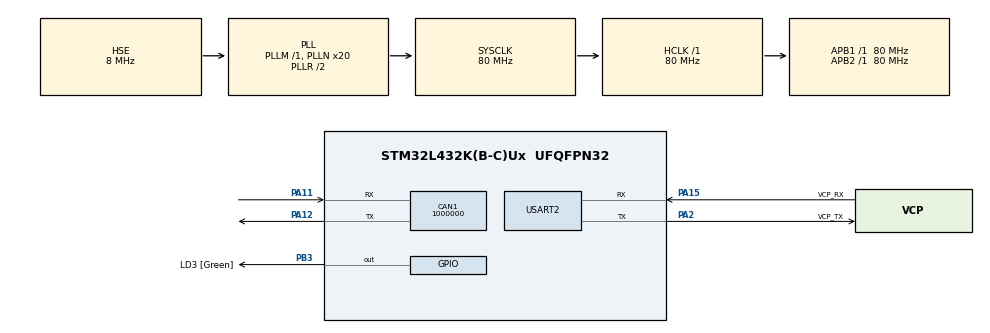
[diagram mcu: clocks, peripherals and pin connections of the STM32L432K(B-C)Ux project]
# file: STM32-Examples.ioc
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CAN1.BS1=CAN_BS1_3TQ
CAN1.CalculateBaudRate=1000000
CAN1.CalculateTimeBit=1000
CAN1.CalculateTimeQuantum=200.0
FREERTOS.INCLUDE_uxTaskGetStackHighWaterMark2=1
FREERTOS.Tasks01=defaultTask,24,128,StartDefaultTask,Default,NULL,Dynamic,NULL,NULL;carReceiveTask,24,400,StartCanReceiveTask,Default,NULL,Static,carReceiveBuffer,carReceiveControlBlock;canTransmitTask,8,400,StartCanTransmitTask,Default,NULL,Static,canTransmitTaskBuffer,canTransmitTaskControlBlock
FREERTOS.configCHECK_FOR_STACK_OVERFLOW=2
FREERTOS.configUSE_NEWLIB_REENTRANT=1
Mcu.Family=STM32L4
Mcu.Name=STM32L432K(B-C)Ux
Mcu.Package=UFQFPN32
NVIC.CAN1_RX0_IRQn=true\:5\:0\:false\:false\:true\:true\:true\:true\:true
NVIC.CAN1_RX1_IRQn=true\:5\:0\:false\:false\:true\:true\:true\:true\:true
NVIC.CAN1_SCE_IRQn=true\:5\:0\:false\:false\:true\:true\:true\:true\:true
NVIC.CAN1_TX_IRQn=true\:5\:0\:false\:false\:true\:true\:true\:true\:true
NVIC.PriorityGroup=NVIC_PRIORITYGROUP_4
NVIC.TIM1_UP_TIM16_IRQn=true\:15\:0\:false\:false\:true\:false\:false\:true\:true
NVIC.TimeBase=TIM1_UP_TIM16_IRQn
NVIC.TimeBaseIP=TIM16
PA0.GPIO_Label=MCO [High speed clock in]
PA0.Mode=HSE-External-Clock-Source-for-LittleOrca
PA0.Signal=RCC_CK_IN
PA11.Mode=CAN_Activate
PA11.Signal=CAN1_RX
PA12.Mode=CAN_Activate
PA12.Signal=CAN1_TX
PA13\ (JTMS-SWDIO).GPIO_Label=SWDIO
PA13\ (JTMS-SWDIO).Mode=Serial_Wire
PA13\ (JTMS-SWDIO).Signal=SYS_JTMS-SWDIO
PA14\ (JTCK-SWCLK).GPIO_Label=SWCLK
PA14\ (JTCK-SWCLK).Mode=Serial_Wire
PA14\ (JTCK-SWCLK).Signal=SYS_JTCK-SWCLK
PA15\ (JTDI).GPIO_Label=VCP_RX
PA15\ (JTDI).Mode=Asynchronous
PA15\ (JTDI).Signal=USART2_RX
PA2.GPIO_Label=VCP_TX
PA2.Mode=Asynchronous
PA2.Signal=USART2_TX
PB3\ (JTDO-TRACESWO).GPIO_Label=LD3 [Green]
PB3\ (JTDO-TRACESWO).Signal=GPIO_Output
PC14-OSC32_IN\ (PC14).Mode=LSE-External-Oscillator
PC14-OSC32_IN\ (PC14).Signal=RCC_OSC32_IN
PC15-OSC32_OUT\ (PC15).Mode=LSE-External-Oscillator
PC15-OSC32_OUT\ (PC15).Signal=RCC_OSC32_OUT
ProjectManager.HeapSize=0x200
ProjectManager.StackSize=0x400
ProjectManager.TargetToolchain=CMake
RCC.ADCFreq_Value=32000000
RCC.AHBFreq_Value=80000000
RCC.APB1Freq_Value=80000000
RCC.APB1TimFreq_Value=80000000
RCC.APB2Freq_Value=80000000
RCC.APB2TimFreq_Value=80000000
RCC.CortexFreq_Value=80000000
RCC.HCLKFreq_Value=80000000
RCC.HSE_VALUE=8000000
RCC.HSI16_VALUE=16000000
RCC.HSI48_VALUE=48000000
RCC.HSI_VALUE=16000000
RCC.MSI_VALUE=4000000
RCC.PLLMUL=RCC_PLLMUL_4
RCC.PLLN=20
RCC.PLLSourceVirtual=RCC_PLLSOURCE_HSE
RCC.SYSCLKFreq_VALUE=80000000
RCC.SYSCLKSource=RCC_SYSCLKSOURCE_PLLCLK
RCC.USBFreq_Value=32000000
RCC.VCOOutputFreq_Value=160000000
USART2.VirtualMode-Asynchronous=VM_ASYNC
VP_FREERTOS_VS_CMSIS_V2.Mode=CMSIS_V2
VP_SYS_VS_tim16.Mode=TIM16
board=NUCLEO-L432KC

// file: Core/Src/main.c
/* USER CODE BEGIN Header */
/**
  ******************************************************************************
  * @file           : main.c
  * @brief          : Main program body
  ******************************************************************************
  * @attention
  *
  * Copyright (c) 2026 STMicroelectronics.
  * All rights reserved.
  *
  * This software is licensed under terms that can be found in the LICENSE file
  * in the root directory of this software component.
  * If no LICENSE file comes with this software, it is provided AS-IS.
  *
  ******************************************************************************
  */
/* USER CODE END Header */
#include "main.h"
#include "cmsis_os.h"

/* USER CODE BEGIN Includes */
#include "ecocar_can.h"
/* USER CODE END Includes */

typedef StaticTask_t osStaticThreadDef_t;

/* USER CODE BEGIN PM */
fdcanBytes_t test_b;
fdcanBytes_t test_b2;
/* USER CODE END PM */

CAN_HandleTypeDef hcan1;

UART_HandleTypeDef huart2;

/* Definitions for defaultTask */
osThreadId_t defaultTaskHandle;
const osThreadAttr_t defaultTask_attributes = {
  .name = "defaultTask",
  .stack_size = 128 * 4,
  .priority = (osPriority_t) osPriorityNormal,
};
/* Definitions for carReceiveTask */
osThreadId_t carReceiveTaskHandle;
uint32_t carReceiveBuffer[ 400 ];
osStaticThreadDef_t carReceiveControlBlock;
const osThreadAttr_t carReceiveTask_attributes = {
  .name = "carReceiveTask",
  .cb_mem = &carReceiveControlBlock,
  .cb_size = sizeof(carReceiveControlBlock),
  .stack_mem = &carReceiveBuffer[0],
  .stack_size = sizeof(carReceiveBuffer),
  .priority = (osPriority_t) osPriorityNormal,
};
/* Definitions for canTransmitTask */
osThreadId_t canTransmitTaskHandle;
uint32_t canTransmitTaskBuffer[ 400 ];
osStaticThreadDef_t canTransmitTaskControlBlock;
const osThreadAttr_t canTransmitTask_attributes = {
  .name = "canTransmitTask",
  .cb_mem = &canTransmitTaskControlBlock,
  .cb_size = sizeof(canTransmitTaskControlBlock),
  .stack_mem = &canTransmitTaskBuffer[0],
  .stack_size = sizeof(canTransmitTaskBuffer),
  .priority = (osPriority_t) osPriorityLow,
};

void SystemClock_Config(void);
static void MX_GPIO_Init(void);
static void MX_CAN1_Init(void);
static void MX_USART2_UART_Init(void);
void StartDefaultTask(void *argument);
void StartCanReceiveTask(void *argument);
void StartCanTransmitTask(void *argument);

int main(void)
{

  /* MCU Configuration--------------------------------------------------------*/

  /* Reset of all peripherals, Initializes the Flash interface and the Systick. */
  HAL_Init();

  /* Configure the system clock */
  SystemClock_Config();

  /* Initialize all configured peripherals */
  MX_GPIO_Init();
  MX_CAN1_Init();
  MX_USART2_UART_Init();

  /* Init scheduler */
  osKernelInitialize();

  /* Create the thread(s) */
  /* creation of defaultTask */
  defaultTaskHandle = osThreadNew(StartDefaultTask, NULL, &defaultTask_attributes);

  /* creation of carReceiveTask */
  carReceiveTaskHandle = osThreadNew(StartCanReceiveTask, NULL, &carReceiveTask_attributes);

  /* creation of canTransmitTask */
  canTransmitTaskHandle = osThreadNew(StartCanTransmitTask, NULL, &canTransmitTask_attributes);

  /* Start scheduler */
  osKernelStart();

  /* We should never get here as control is now taken by the scheduler */

  /* Infinite loop */
  while (1)
  {

  }
}

void SystemClock_Config(void)
{
  RCC_OscInitTypeDef RCC_OscInitStruct = {0};
  RCC_ClkInitTypeDef RCC_ClkInitStruct = {0};

  /** Configure the main internal regulator output voltage
  */
  if (HAL_PWREx_ControlVoltageScaling(PWR_REGULATOR_VOLTAGE_SCALE1) != HAL_OK)
  {
    Error_Handler();
  }

  /** Initializes the RCC Oscillators according to the specified parameters
  * in the RCC_OscInitTypeDef structure.
  */
  RCC_OscInitStruct.OscillatorType = RCC_OSCILLATORTYPE_HSE;
  RCC_OscInitStruct.HSEState = RCC_HSE_BYPASS;
  RCC_OscInitStruct.PLL.PLLState = RCC_PLL_ON;
  RCC_OscInitStruct.PLL.PLLSource = RCC_PLLSOURCE_HSE;
  RCC_OscInitStruct.PLL.PLLM = 1;
  RCC_OscInitStruct.PLL.PLLN = 20;
  RCC_OscInitStruct.PLL.PLLP = RCC_PLLP_DIV7;
  RCC_OscInitStruct.PLL.PLLQ = RCC_PLLQ_DIV2;
  RCC_OscInitStruct.PLL.PLLR = RCC_PLLR_DIV2;
  if (HAL_RCC_OscConfig(&RCC_OscInitStruct) != HAL_OK)
  {
    Error_Handler();
  }

  /** Initializes the CPU, AHB and APB buses clocks
  */
  RCC_ClkInitStruct.ClockType = RCC_CLOCKTYPE_HCLK|RCC_CLOCKTYPE_SYSCLK
                              |RCC_CLOCKTYPE_PCLK1|RCC_CLOCKTYPE_PCLK2;
  RCC_ClkInitStruct.SYSCLKSource = RCC_SYSCLKSOURCE_PLLCLK;
  RCC_ClkInitStruct.AHBCLKDivider = RCC_SYSCLK_DIV1;
  RCC_ClkInitStruct.APB1CLKDivider = RCC_HCLK_DIV1;
  RCC_ClkInitStruct.APB2CLKDivider = RCC_HCLK_DIV1;

  if (HAL_RCC_ClockConfig(&RCC_ClkInitStruct, FLASH_LATENCY_4) != HAL_OK)
  {
    Error_Handler();
  }
}

static void MX_CAN1_Init(void)
{

  hcan1.Instance = CAN1;
  hcan1.Init.Prescaler = 16;
  hcan1.Init.Mode = CAN_MODE_NORMAL;
  hcan1.Init.SyncJumpWidth = CAN_SJW_1TQ;
  hcan1.Init.TimeSeg1 = CAN_BS1_3TQ;
  hcan1.Init.TimeSeg2 = CAN_BS2_1TQ;
  hcan1.Init.TimeTriggeredMode = DISABLE;
  hcan1.Init.AutoBusOff = DISABLE;
  hcan1.Init.AutoWakeUp = DISABLE;
  hcan1.Init.AutoRetransmission = DISABLE;
  hcan1.Init.ReceiveFifoLocked = DISABLE;
  hcan1.Init.TransmitFifoPriority = DISABLE;
  if (HAL_CAN_Init(&hcan1) != HAL_OK)
  {
    Error_Handler();
  }

}

static void MX_USART2_UART_Init(void)
{

  huart2.Instance = USART2;
  huart2.Init.BaudRate = 115200;
  huart2.Init.WordLength = UART_WORDLENGTH_8B;
  huart2.Init.StopBits = UART_STOPBITS_1;
  huart2.Init.Parity = UART_PARITY_NONE;
  huart2.Init.Mode = UART_MODE_TX_RX;
  huart2.Init.HwFlowCtl = UART_HWCONTROL_NONE;
  huart2.Init.OverSampling = UART_OVERSAMPLING_16;
  huart2.Init.OneBitSampling = UART_ONE_BIT_SAMPLE_DISABLE;
  huart2.AdvancedInit.AdvFeatureInit = UART_ADVFEATURE_NO_INIT;
  if (HAL_UART_Init(&huart2) != HAL_OK)
  {
    Error_Handler();
  }

}

static void MX_GPIO_Init(void)
{
  GPIO_InitTypeDef GPIO_InitStruct = {0};

  /* GPIO Ports Clock Enable */
  __HAL_RCC_GPIOC_CLK_ENABLE();
  __HAL_RCC_GPIOA_CLK_ENABLE();
  __HAL_RCC_GPIOB_CLK_ENABLE();

  /*Configure GPIO pin Output Level */
  HAL_GPIO_WritePin(LD3_GPIO_Port, LD3_Pin, GPIO_PIN_RESET);

  /*Configure GPIO pin : LD3_Pin */
  GPIO_InitStruct.Pin = LD3_Pin;
  GPIO_InitStruct.Mode = GPIO_MODE_OUTPUT_PP;
  GPIO_InitStruct.Pull = GPIO_NOPULL;
  GPIO_InitStruct.Speed = GPIO_SPEED_FREQ_LOW;
  HAL_GPIO_Init(LD3_GPIO_Port, &GPIO_InitStruct);

}

void StartDefaultTask(void *argument)
{
  for(;;)
  {
    osDelay(1);
  }
}

void StartCanReceiveTask(void *argument)
{
  for(;;)
  {
    osDelay(1);
  }
}

void StartCanTransmitTask(void *argument)
{
  for(;;)
  {
    osDelay(1);
  }
}

void HAL_TIM_PeriodElapsedCallback(TIM_HandleTypeDef *htim)
{
  if (htim->Instance == TIM16)
  {
    HAL_IncTick();
  }
}

void Error_Handler(void)
{
  __disable_irq();
  while (1)
  {
  }
}
